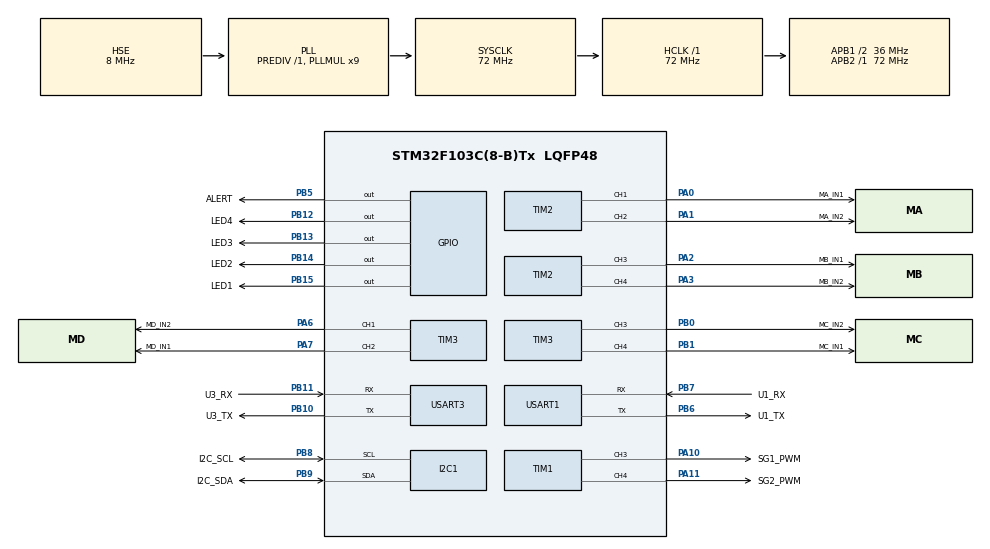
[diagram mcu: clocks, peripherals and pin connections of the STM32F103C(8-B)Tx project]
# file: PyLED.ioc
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Dma.Request0=USART1_RX
Dma.Request1=USART1_TX
Dma.Request2=USART3_RX
Dma.Request3=USART3_TX
Dma.USART1_RX.0.Direction=DMA_PERIPH_TO_MEMORY
Dma.USART1_RX.0.Instance=DMA1_Channel5
Dma.USART1_RX.0.MemDataAlignment=DMA_MDATAALIGN_BYTE
Dma.USART1_RX.0.MemInc=DMA_MINC_ENABLE
Dma.USART1_RX.0.Mode=DMA_NORMAL
Dma.USART1_RX.0.PeriphDataAlignment=DMA_PDATAALIGN_BYTE
Dma.USART1_RX.0.PeriphInc=DMA_PINC_DISABLE
Dma.USART1_RX.0.Priority=DMA_PRIORITY_LOW
Dma.USART1_TX.1.Direction=DMA_MEMORY_TO_PERIPH
Dma.USART1_TX.1.Instance=DMA1_Channel4
Dma.USART1_TX.1.MemDataAlignment=DMA_MDATAALIGN_BYTE
Dma.USART1_TX.1.MemInc=DMA_MINC_ENABLE
Dma.USART1_TX.1.Mode=DMA_NORMAL
Dma.USART1_TX.1.PeriphDataAlignment=DMA_PDATAALIGN_BYTE
Dma.USART1_TX.1.PeriphInc=DMA_PINC_DISABLE
Dma.USART1_TX.1.Priority=DMA_PRIORITY_LOW
Dma.USART3_RX.2.Direction=DMA_PERIPH_TO_MEMORY
Dma.USART3_RX.2.Instance=DMA1_Channel3
Dma.USART3_RX.2.MemDataAlignment=DMA_MDATAALIGN_BYTE
Dma.USART3_RX.2.MemInc=DMA_MINC_ENABLE
Dma.USART3_RX.2.Mode=DMA_NORMAL
Dma.USART3_RX.2.PeriphDataAlignment=DMA_PDATAALIGN_BYTE
Dma.USART3_RX.2.PeriphInc=DMA_PINC_DISABLE
Dma.USART3_RX.2.Priority=DMA_PRIORITY_LOW
Dma.USART3_TX.3.Direction=DMA_MEMORY_TO_PERIPH
Dma.USART3_TX.3.Instance=DMA1_Channel2
Dma.USART3_TX.3.MemDataAlignment=DMA_MDATAALIGN_BYTE
Dma.USART3_TX.3.MemInc=DMA_MINC_ENABLE
Dma.USART3_TX.3.Mode=DMA_NORMAL
Dma.USART3_TX.3.PeriphDataAlignment=DMA_PDATAALIGN_BYTE
Dma.USART3_TX.3.PeriphInc=DMA_PINC_DISABLE
Dma.USART3_TX.3.Priority=DMA_PRIORITY_LOW
Mcu.Family=STM32F1
Mcu.Name=STM32F103C(8-B)Tx
Mcu.Package=LQFP48
NVIC.DMA1_Channel2_IRQn=true\:0\:0\:false\:false\:true\:false\:true\:true
NVIC.DMA1_Channel3_IRQn=true\:0\:0\:false\:false\:true\:false\:true\:true
NVIC.DMA1_Channel4_IRQn=true\:0\:0\:false\:false\:true\:false\:true\:true
NVIC.DMA1_Channel5_IRQn=true\:0\:0\:false\:false\:true\:false\:true\:true
NVIC.PriorityGroup=NVIC_PRIORITYGROUP_4
NVIC.USART1_IRQn=true\:0\:0\:false\:false\:true\:false\:true\:true
NVIC.USART3_IRQn=true\:0\:0\:false\:false\:true\:true\:true\:true
PA0-WKUP.GPIO_Label=MA_IN1
PA0-WKUP.Signal=S_TIM2_CH1_ETR
PA1.GPIO_Label=MA_IN2
PA1.Signal=S_TIM2_CH2
PA10.GPIO_Label=SG1_PWM
PA10.Signal=S_TIM1_CH3
PA11.GPIO_Label=SG2_PWM
PA11.Signal=S_TIM1_CH4
PA13.Mode=Serial_Wire
PA13.Signal=SYS_JTMS-SWDIO
PA14.Mode=Serial_Wire
PA14.Signal=SYS_JTCK-SWCLK
PA2.GPIO_Label=MB_IN1
PA2.Signal=S_TIM2_CH3
PA3.GPIO_Label=MB_IN2
PA3.Signal=S_TIM2_CH4
PA6.GPIO_Label=MD_IN2
PA6.Signal=S_TIM3_CH1
PA7.GPIO_Label=MD_IN1
PA7.Signal=S_TIM3_CH2
PB0.GPIO_Label=MC_IN2
PB0.Signal=S_TIM3_CH3
PB1.GPIO_Label=MC_IN1
PB1.Signal=S_TIM3_CH4
PB10.GPIO_Label=U3_TX
PB10.Mode=Asynchronous
PB10.Signal=USART3_TX
PB11.GPIO_Label=U3_RX
PB11.Mode=Asynchronous
PB11.Signal=USART3_RX
PB12.GPIO_Label=LED4
PB12.Signal=GPIO_Output
PB13.GPIO_Label=LED3
PB13.Signal=GPIO_Output
PB14.GPIO_Label=LED2
PB14.Signal=GPIO_Output
PB15.GPIO_Label=LED1
PB15.Signal=GPIO_Output
PB5.GPIO_Label=ALERT
PB5.Signal=GPIO_Output
PB6.GPIO_Label=U1_TX
PB6.Mode=Asynchronous
PB6.Signal=USART1_TX
PB7.GPIO_Label=U1_RX
PB7.Mode=Asynchronous
PB7.Signal=USART1_RX
PB8.GPIO_Label=I2C_SCL
PB8.Mode=I2C
PB8.Signal=I2C1_SCL
PB9.GPIO_Label=I2C_SDA
PB9.Mode=I2C
PB9.Signal=I2C1_SDA
PD0-OSC_IN.Mode=HSE-External-Oscillator
PD0-OSC_IN.Signal=RCC_OSC_IN
PD1-OSC_OUT.Mode=HSE-External-Oscillator
PD1-OSC_OUT.Signal=RCC_OSC_OUT
ProjectManager.HeapSize=0x200
ProjectManager.StackSize=0x400
ProjectManager.TargetToolchain=MDK-ARM V5.32
RCC.AHBFreq_Value=72000000
RCC.APB1CLKDivider=RCC_HCLK_DIV2
RCC.APB1Freq_Value=36000000
RCC.APB1TimFreq_Value=72000000
RCC.APB2Freq_Value=72000000
RCC.APB2TimFreq_Value=72000000
RCC.HCLKFreq_Value=72000000
RCC.PLLMUL=RCC_PLL_MUL9
RCC.PLLSourceVirtual=RCC_PLLSOURCE_HSE
RCC.SYSCLKFreq_VALUE=72000000
RCC.SYSCLKSource=RCC_SYSCLKSOURCE_PLLCLK
RCC.USBFreq_Value=72000000
SH.S_TIM1_CH3.0=TIM1_CH3,PWM Generation3 CH3
SH.S_TIM1_CH4.0=TIM1_CH4,PWM Generation4 CH4
SH.S_TIM2_CH1_ETR.0=TIM2_CH1,PWM Generation1 CH1
SH.S_TIM2_CH2.0=TIM2_CH2,PWM Generation2 CH2
SH.S_TIM2_CH3.0=TIM2_CH3,PWM Generation3 CH3
SH.S_TIM2_CH4.0=TIM2_CH4,PWM Generation4 CH4
SH.S_TIM3_CH1.0=TIM3_CH1,PWM Generation1 CH1
SH.S_TIM3_CH2.0=TIM3_CH2,PWM Generation2 CH2
SH.S_TIM3_CH3.0=TIM3_CH3,PWM Generation3 CH3
SH.S_TIM3_CH4.0=TIM3_CH4,PWM Generation4 CH4
TIM1.Channel-PWM\ Generation3\ CH3=TIM_CHANNEL_3
TIM1.Channel-PWM\ Generation4\ CH4=TIM_CHANNEL_4
TIM2.Channel-PWM\ Generation1\ CH1=TIM_CHANNEL_1
TIM2.Channel-PWM\ Generation2\ CH2=TIM_CHANNEL_2
TIM2.Channel-PWM\ Generation3\ CH3=TIM_CHANNEL_3
TIM2.Channel-PWM\ Generation4\ CH4=TIM_CHANNEL_4
TIM3.Channel-PWM\ Generation1\ CH1=TIM_CHANNEL_1
TIM3.Channel-PWM\ Generation2\ CH2=TIM_CHANNEL_2
TIM3.Channel-PWM\ Generation3\ CH3=TIM_CHANNEL_3
TIM3.Channel-PWM\ Generation4\ CH4=TIM_CHANNEL_4
TIM4.Channel-PWM\ Generation1\ CH1=TIM_CHANNEL_1
TIM4.Channel-PWM\ Generation2\ CH2=TIM_CHANNEL_2
TIM4.Channel-PWM\ Generation3\ CH3=TIM_CHANNEL_3
TIM4.Channel-PWM\ Generation4\ CH4=TIM_CHANNEL_4
USART1.VirtualMode=VM_ASYNC
USART3.VirtualMode=VM_ASYNC
VP_TIM1_VS_ClockSourceINT.Mode=Internal
VP_TIM2_VS_ClockSourceINT.Mode=Internal
VP_TIM4_VS_ClockSourceINT.Mode=Internal
board=custom

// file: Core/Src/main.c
/* USER CODE BEGIN Header */
/**
  ******************************************************************************
  * @file           : main.c
  * @brief          : Main program body
  ******************************************************************************
  * @attention
  *
  * Copyright (c) 2026 STMicroelectronics.
  * All rights reserved.
  *
  * This software is licensed under terms that can be found in the LICENSE file
  * in the root directory of this software component.
  * If no LICENSE file comes with this software, it is provided AS-IS.
  *
  ******************************************************************************
  */
/* USER CODE END Header */
#include "main.h"
#include "dma.h"
#include "i2c.h"
#include "tim.h"
#include "usart.h"
#include "gpio.h"

/* USER CODE BEGIN Includes */
#include "string.h"
/* USER CODE END Includes */

/* USER CODE BEGIN PD */
uint8_t rx_buf[32] = {0};
/* USER CODE END PD */

void SystemClock_Config(void);

int main(void)
{

  /* MCU Configuration--------------------------------------------------------*/

  /* Reset of all peripherals, Initializes the Flash interface and the Systick. */
  HAL_Init();

  /* Configure the system clock */
  SystemClock_Config();

  /* Initialize all configured peripherals */
  MX_GPIO_Init();
  MX_DMA_Init();
  MX_I2C1_Init();
  MX_TIM1_Init();
  MX_TIM2_Init();
  MX_TIM3_Init();
  MX_TIM4_Init();
  MX_USART1_UART_Init();
  MX_USART3_UART_Init();
  /* USER CODE BEGIN 2 */
	HAL_UARTEx_ReceiveToIdle_DMA(&huart1, (uint8_t*)rx_buf, sizeof(rx_buf));
  /* USER CODE END 2 */

  /* Infinite loop */
  while (1)
  {

  }
}

void SystemClock_Config(void)
{
  RCC_OscInitTypeDef RCC_OscInitStruct = {0};
  RCC_ClkInitTypeDef RCC_ClkInitStruct = {0};

  /** Initializes the RCC Oscillators according to the specified parameters
  * in the RCC_OscInitTypeDef structure.
  */
  RCC_OscInitStruct.OscillatorType = RCC_OSCILLATORTYPE_HSE;
  RCC_OscInitStruct.HSEState = RCC_HSE_ON;
  RCC_OscInitStruct.HSEPredivValue = RCC_HSE_PREDIV_DIV1;
  RCC_OscInitStruct.HSIState = RCC_HSI_ON;
  RCC_OscInitStruct.PLL.PLLState = RCC_PLL_ON;
  RCC_OscInitStruct.PLL.PLLSource = RCC_PLLSOURCE_HSE;
  RCC_OscInitStruct.PLL.PLLMUL = RCC_PLL_MUL9;
  if (HAL_RCC_OscConfig(&RCC_OscInitStruct) != HAL_OK)
  {
    Error_Handler();
  }

  /** Initializes the CPU, AHB and APB buses clocks
  */
  RCC_ClkInitStruct.ClockType = RCC_CLOCKTYPE_HCLK|RCC_CLOCKTYPE_SYSCLK
                              |RCC_CLOCKTYPE_PCLK1|RCC_CLOCKTYPE_PCLK2;
  RCC_ClkInitStruct.SYSCLKSource = RCC_SYSCLKSOURCE_PLLCLK;
  RCC_ClkInitStruct.AHBCLKDivider = RCC_SYSCLK_DIV1;
  RCC_ClkInitStruct.APB1CLKDivider = RCC_HCLK_DIV2;
  RCC_ClkInitStruct.APB2CLKDivider = RCC_HCLK_DIV1;

  if (HAL_RCC_ClockConfig(&RCC_ClkInitStruct, FLASH_LATENCY_2) != HAL_OK)
  {
    Error_Handler();
  }
}

/* USER CODE BEGIN 4 */
void HAL_UARTEx_RxEventCallback(UART_HandleTypeDef *huart, uint16_t Size)
{
	if(huart->Instance == USART1)
	{
    uint8_t check_sum = (rx_buf[0] + rx_buf[1]) & 0xFF;
		if(rx_buf[0] == 0xAA && rx_buf[3] == 0x55 && check_sum == rx_buf[2]){
      if(rx_buf[1] == 0x01){
        HAL_GPIO_WritePin(LED1_GPIO_Port, LED1_Pin, GPIO_PIN_SET);
      }
		  else if(rx_buf[1] == 0x02){
			  HAL_GPIO_WritePin(LED1_GPIO_Port, LED1_Pin, GPIO_PIN_RESET);
		  }
	  }
    memset(rx_buf, 0, sizeof(rx_buf));
    HAL_UARTEx_ReceiveToIdle_DMA(&huart1, (uint8_t*)rx_buf, sizeof(rx_buf));
  }
}
/* USER CODE END 4 */

void Error_Handler(void)
{
  __disable_irq();
  while (1)
  {
  }
}
